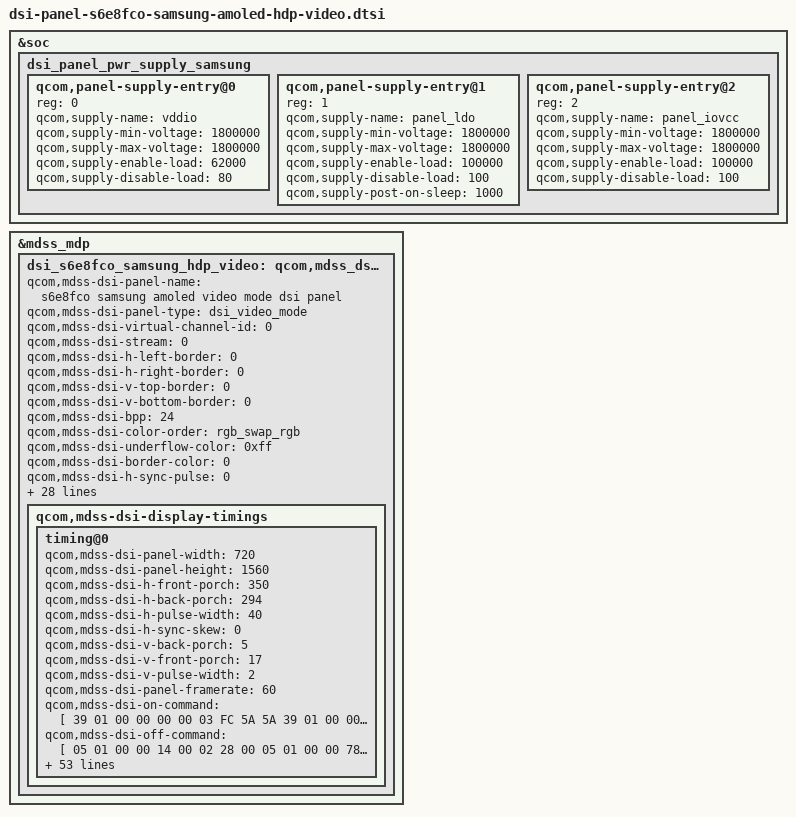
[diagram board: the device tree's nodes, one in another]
/* Copyright (c) 2018, The Linux Foundation. All rights reserved.
 * Copyright (C) 2021 XiaoMi, Inc.
 *
 * This program is free software; you can redistribute it and/or modify
 * it under the terms of the GNU General Public License version 2 and
 * only version 2 as published by the Free Software Foundation.
 *
 * This program is distributed in the hope that it will be useful,
 * but WITHOUT ANY WARRANTY; without even the implied warranty of
 * MERCHANTABILITY or FITNESS FOR A PARTICULAR PURPOSE.  See the
 * GNU General Public License for more details.
 */
&soc {
     dsi_panel_pwr_supply_samsung: dsi_panel_pwr_supply_samsung {

		qcom,panel-supply-entry@0 {
			reg = <0>;
			qcom,supply-name = "vddio";
			qcom,supply-min-voltage = <1800000>;
			qcom,supply-max-voltage = <1800000>;
			qcom,supply-enable-load = <62000>;
			qcom,supply-disable-load = <80>;
		};
		qcom,panel-supply-entry@1 {
			reg = <1>;
			qcom,supply-name = "panel_ldo";
			qcom,supply-min-voltage = <1800000>;
			qcom,supply-max-voltage = <1800000>;
			qcom,supply-enable-load = <100000>;
			qcom,supply-disable-load = <100>;
			qcom,supply-post-on-sleep = <1000>;
			};
		qcom,panel-supply-entry@2 {
			reg = <2>;
			qcom,supply-name = "panel_iovcc";
			qcom,supply-min-voltage = <1800000>;
			qcom,supply-max-voltage = <1800000>;
			qcom,supply-enable-load = <100000>;
			qcom,supply-disable-load = <100>;
			//qcom,supply-pre-on-sleep = <1>;
		};
	};
};

&mdss_mdp {
	dsi_s6e8fco_samsung_hdp_video: qcom,mdss_dsi_s6e8fco_samsung_hdp_video {
		qcom,mdss-dsi-panel-name =
			"s6e8fco samsung amoled video mode dsi panel";
		qcom,mdss-dsi-panel-type = "dsi_video_mode";

		qcom,mdss-dsi-virtual-channel-id = <0>;
		qcom,mdss-dsi-stream = <0>;
		qcom,mdss-dsi-h-left-border = <0>;
		qcom,mdss-dsi-h-right-border = <0>;
		qcom,mdss-dsi-v-top-border = <0>;
		qcom,mdss-dsi-v-bottom-border = <0>;
		qcom,mdss-dsi-bpp = <24>;
		qcom,mdss-dsi-color-order = "rgb_swap_rgb";
		qcom,mdss-dsi-underflow-color = <0xff>;
		qcom,mdss-dsi-border-color = <0>;
		qcom,mdss-dsi-h-sync-pulse = <0>;
		qcom,mdss-dsi-traffic-mode = "burst_mode";
		qcom,mdss-dsi-lane-map = "lane_map_0123";
		qcom,mdss-dsi-bllp-eof-power-mode;
		qcom,mdss-dsi-bllp-power-mode;
		qcom,mdss-dsi-tx-eot-append;
		qcom,mdss-dsi-lane-0-state;
		qcom,mdss-dsi-lane-1-state;
		qcom,mdss-dsi-lane-2-state;
		qcom,mdss-dsi-lane-3-state;
		qcom,mdss-dsi-panel-physical-type = "oled";
		qcom,mdss-dsi-dma-trigger = "trigger_sw";
		qcom,mdss-dsi-mdp-trigger = "none";
		qcom,mdss-dsi-bl-inverted-dbv;
		qcom,mdss-dsi-lp11-init;
		qcom,bl-update-flag = "delay_until_first_frame";
		qcom,mdss-dsi-samsung-flag;
		qcom,mdss-dsi-bl-pmic-control-type = "bl_ctrl_dcs";
		qcom,mdss-dsi-reset-sequence = <1 12>, <0 2>, <1 10>;
		qcom,mdss-pan-physical-width-dimension = <65>;
		qcom,mdss-pan-physical-height-dimension = <140>;
		qcom,disp-doze-lbm-backlight = <15>;
		qcom,disp-doze-hbm-backlight = <190>;
		qcom,mdss-dsi-panel-dc-threshold = <610>;

		qcom,disp-fod-dim-lut = <
			/* brightness, alpha */
			0	0XFF
			3	0XEB
			13	0XDD
			31	0XD0
			58	0XC4
			96	0XB8
			143	0XAD
			200	0XA2
			269	0X97
			348	0X8D
			439	0X83
			551	0X78
			667	0X6E
			794	0X65
			934	0X5B
			1086	0X52
			1250	0X48
			1427	0X3F
			1618	0X36
			1821	0X2D
			2047	0X24
		>;
		qcom,disp-dc-dim-lut = <
			/* brightness, alpha */
			0	0xFF
			1	0xF1
			4	0xE5
			9	0xD9
			18	0xCB
			29	0xBF
			43	0xB2
			60	0xA6
			81	0x99
			106	0x8B
			132	0x7F
			163	0x73
			198	0x66
			237	0x59
			277	0x4C
			323	0x40
			373	0x33
			428	0x25
			481	0x1A
			544	0xC
			610	0x0
		>;

		qcom,mdss-dsi-display-timings {
			timing@0 {
				qcom,mdss-dsi-panel-width = <720>;
				qcom,mdss-dsi-panel-height = <1560>;
				qcom,mdss-dsi-h-front-porch = <350>;
				qcom,mdss-dsi-h-back-porch = <294>;
				qcom,mdss-dsi-h-pulse-width = <40>;
				qcom,mdss-dsi-h-sync-skew = <0>;
				qcom,mdss-dsi-v-back-porch = <5>;
				qcom,mdss-dsi-v-front-porch = <17>;
				qcom,mdss-dsi-v-pulse-width = <2>;
				qcom,mdss-dsi-panel-framerate = <60>;
				qcom,mdss-dsi-on-command = [
				39 01 00 00 00 00 03 FC 5A 5A
				39 01 00 00 00 00 03 51 00 00
				15 01 00 00 00 00 02 53 20
				05 01 00 00 32 00 02 11 00
				05 01 00 00 00 00 02 29 00
				39 01 00 00 00 00 03 B0 04 ED
				39 01 00 00 00 00 0A ED E4 08 96 A4 2A 72 E2 CA 00
				39 01 00 00 00 00 03 FC A5 A5
				39 01 00 00 00 00 03 F0 5A 5A
				39 01 00 00 00 00 03 FC 5A 5A
				39 01 00 00 00 00 02 E1 93
				39 01 00 00 00 00 03 B0 05 F4
				39 01 00 00 00 00 02 F4 03
				39 01 00 00 00 00 04 ED 01 81 04
				39 01 00 00 00 00 03 F0 A5 A5
				39 01 00 00 00 00 03 FC A5 A5];
				qcom,mdss-dsi-off-command = [
				  05 01 00 00 14 00 02 28 00
				  05 01 00 00 78 00 02 10 00
				];

				qcom,mdss-dsi-acl-on-command = [
				  15 01 00 00 00 00 02 55 01
				];
				qcom,mdss-dsi-acl-off-command = [
				  15 01 00 00 00 00 02 55 00
				];
				qcom,mdss-dsi-post-panel-on-command = [
				  15 01 00 00 00 00 02 55 01
				];
				qcom,mdss-dsi-doze-lbm-command = [
				  15 01 00 00 00 00 02 53 20
				  39 01 00 00 00 00 03 51 00 0F
				];
				qcom,mdss-dsi-doze-hbm-command = [
				  15 01 00 00 00 00 02 53 20
				  39 01 00 00 00 00 03 51 00 BE
				];
				qcom,mdss-dsi-nolp-command = [
				  15 01 00 00 00 00 02 53 28
				];

				qcom,mdss-dsi-dimming-brightness-command = [
				  15 01 00 00 00 00 02 53 20
				  39 01 00 00 00 00 03 51 00 BE
				];
				qcom,mdss-dsi-brightness-command = [
				  39 01 00 00 00 00 03 51 00 BE
				];

				qcom,mdss-dsi-dimming-enable-command = [
				  15 01 00 00 00 00 02 53 28
				];
				qcom,mdss-dsi-dispparam-hbm-fod-on-command = [
					15 01 00 00 10 00 02 53 E0];
				qcom,mdss-dsi-dispparam-hbm-fod-off-command = [
					15 01 00 00 10 00 02 53 20];
				qcom,mdss-dsi-dispparam-hbm-fod-off-doze-lbm-on-command = [
					15 01 00 00 10 00 02 53 23];
				qcom,mdss-dsi-dispparam-hbm-fod-off-doze-hbm-on-command = [
					15 01 00 00 10 00 02 53 22];

				qcom,mdss-dsi-post-on-command-state = "dsi_hs_mode";

				qcom,mdss-dsi-doze-lbm-command-state = "dsi_hs_mode";
				qcom,mdss-dsi-doze-hbm-command-state = "dsi_hs_mode";
				qcom,mdss-dsi-nolp-command-state = "dsi_hs_mode";
				qcom,mdss-dsi-dimming-brightness-command-state = "dsi_hs_mode";
				qcom,mdss-dsi-brightness-command-state = "dsi_hs_mode";
				qcom,mdss-dsi-dimming-enable-command-state= "dsi_hs_mode";
				qcom,mdss-dsi-acl-on-command-state = "dsi_hs_mode";
				qcom,mdss-dsi-acl-off-command-state = "dsi_hs_mode";
				qcom,mdss-dsi-on-command-state = "dsi_hs_mode";
				qcom,mdss-dsi-off-command-state = "dsi_hs_mode";
				qcom,mdss-dsi-dispparam-hbm-fod-on-command-state = "dsi_lp_mode";
				qcom,mdss-dsi-dispparam-hbm-fod-off-command-state = "dsi_lp_mode";
				qcom,mdss-dsi-dispparam-hbm-fod-off-doze-lbm-on-command-state = "dsi_hs_mode";
				qcom,mdss-dsi-dispparam-hbm-fod-off-doze-hbm-on-command-state = "dsi_hs_mode";
			};
		};
	};
};

